# StarFive VisionFive 2 v1.3b register map
File version: 0.1
Registers are 32-bit, read-write, no defined reset value unless marked. A register's access mark holds for its fields unless they carry their own. Offsets are from the block's base; [hi:lo] are bit positions; 'fields as' and 'values as' point back to an identical list.

## starfive_jh7110_stgcrg_0 — From starfive,jh7110-stgcrg, peripheral generator
Base 0x10230000
0x00 clk_hifi4_core — Clock HIFI4 Core
  [31] clk_icg — 1: Clock enable, 0: Clock disable
0x04 clk_usb_apb — Clock USB APB
  [31] clk_icg — 1: Clock enable, 0: Clock disable
0x08 clk_usb_utmi_apb — Clock USB UTMI APB
  [31] clk_icg — 1: Clock enable, 0: Clock disable
0x0C clk_usb_axi — Clock USB AXI
  [31] clk_icg — 1: Clock enable, 0: Clock disable
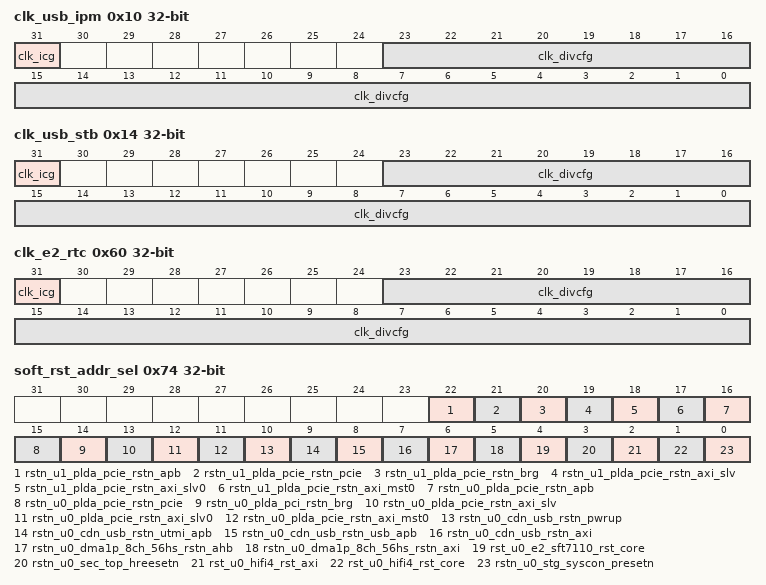
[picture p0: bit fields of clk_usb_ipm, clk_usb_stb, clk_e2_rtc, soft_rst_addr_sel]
0x10 clk_usb_ipm — Clock USB AXI
  [31] clk_icg — 1: Clock enable, 0: Clock disable
  [23:0] clk_divcfg — Clock divider coefficient: Max=2, Default=2, Min=2, Typical=2
0x14 clk_usb_stb — Clock USB STB
  [31] clk_icg — 1: Clock enable, 0: Clock disable
  [23:0] clk_divcfg — Clock divider coefficient: Max=4, Default=4, Min=4, Typical=4
0x18 clk_usb_app125 — Clock USB APP 125
  [31] clk_icg — 1: Clock enable, 0: Clock disable
0x1C clk_usb_refclk — Clock USB Reference Clock
  [23:0] clk_divcfg — Clock divider coefficient: Max=2, Default=2, Min=2, Typical=2
0x20 clk_u0_pcie_axi_mst0 — U0 Clock PCIe AXI MST 0
  [31] clk_icg — 1: Clock enable, 0: Clock disable
0x24 clk_u0_pcie_apb — U0 Clock PCIe APB
  [31] clk_icg — 1: Clock enable, 0: Clock disable
0x28 clk_u0_pcie_tl — U0 Clock PCIe TL
  [31] clk_icg — 1: Clock enable, 0: Clock disable
0x2C clk_u1_pcie_axi_mst0 — U1 Clock PCIe AXI MST 0
  [31] clk_icg — 1: Clock enable, 0: Clock disable
0x30 clk_u1_pcie_apb — U1 Clock PCIe APB
  [31] clk_icg — 1: Clock enable, 0: Clock disable
0x34 clk_u1_pcie_tl — U1 Clock PCIe TL
  [31] clk_icg — 1: Clock enable, 0: Clock disable
0x38 clk_pcie01_slv_dec_main — Clock PCIe 01 SLV DEC Main
  [31] clk_icg — 1: Clock enable, 0: Clock disable
0x3C clk_sec_hclk — Clock Security HCLK
  [31] clk_icg — 1: Clock enable, 0: Clock disable
0x40 clk_sec_misc_ahb — Clock Security Miscellaneous AHB
  [31] clk_icg — 1: Clock enable, 0: Clock disable
0x44 clk_stg_mtrx_group0_main — Clock STG MTRX Group 0 Main
  [31] clk_icg — 1: Clock enable, 0: Clock disable
0x48 clk_stg_mtrx_group0_bus — Clock STG MTRX Group 0 Bus
  [31] clk_icg — 1: Clock enable, 0: Clock disable
0x4C clk_stg_mtrx_group0_stg — Clock STG MTRX Group 0 STG
  [31] clk_icg — 1: Clock enable, 0: Clock disable
0x50 clk_stg_mtrx_group1_main — Clock STG MTRX Group 1 Main
  [31] clk_icg — 1: Clock enable, 0: Clock disable
0x54 clk_stg_mtrx_group1_bus — Clock STG MTRX Group 1 Bus
  [31] clk_icg — 1: Clock enable, 0: Clock disable
0x58 clk_stg_mtrx_group1_stg — Clock STG MTRX Group 1 STG
  [31] clk_icg — 1: Clock enable, 0: Clock disable
0x5C clk_stg_mtrx_group1_hifi — Clock STG MTRX Group 1 HIFI
  [31] clk_icg — 1: Clock enable, 0: Clock disable
0x60 clk_e2_rtc — Clock E2 RTC
  [31] clk_icg — 1: Clock enable, 0: Clock disable
  [23:0] clk_divcfg — Clock divider coefficient: Max=24, Default=24, Min=24, Typical=24
0x64 clk_e2_core — Clock E2 Core
  [31] clk_icg — 1: Clock enable, 0: Clock disable
0x68 clk_e2_dbg — Clock E2 DBG
  [31] clk_icg — 1: Clock enable, 0: Clock disable
0x6C clk_dma_axi — Clock DMA AXI
  [31] clk_icg — 1: Clock enable, 0: Clock disable
0x70 clk_dma_ahb — Clock DMA AHB
  [31] clk_icg — 1: Clock enable, 0: Clock disable
0x74 soft_rst_addr_sel — Software RESET Address Selector
  [22] rstn_u1_plda_pcie_rstn_apb — 1: Assert reset, 0: De-assert reset
  [21] rstn_u1_plda_pcie_rstn_pcie — 1: Assert reset, 0: De-assert reset
  [20] rstn_u1_plda_pcie_rstn_brg — 1: Assert reset, 0: De-assert reset
  [19] rstn_u1_plda_pcie_rstn_axi_slv — 1: Assert reset, 0: De-assert reset
  [18] rstn_u1_plda_pcie_rstn_axi_slv0 — 1: Assert reset, 0: De-assert reset
  [17] rstn_u1_plda_pcie_rstn_axi_mst0 — 1: Assert reset, 0: De-assert reset
  [16] rstn_u0_plda_pcie_rstn_apb — 1: Assert reset, 0: De-assert reset
  [15] rstn_u0_plda_pcie_rstn_pcie — 1: Assert reset, 0: De-assert reset
  [14] rstn_u0_plda_pci_rstn_brg — 1: Assert reset, 0: De-assert reset
  [13] rstn_u0_plda_pcie_rstn_axi_slv — 1: Assert reset, 0: De-assert reset
  [12] rstn_u0_plda_pcie_rstn_axi_slv0 — 1: Assert reset, 0: De-assert reset
  [11] rstn_u0_plda_pcie_rstn_axi_mst0 — 1: Assert reset, 0: De-assert reset
  [10] rstn_u0_cdn_usb_rstn_pwrup — 1: Assert reset, 0: De-assert reset
  [9] rstn_u0_cdn_usb_rstn_utmi_apb — 1: Assert reset, 0: De-assert reset
  [8] rstn_u0_cdn_usb_rstn_usb_apb — 1: Assert reset, 0: De-assert reset
  [7] rstn_u0_cdn_usb_rstn_axi — 1: Assert reset, 0: De-assert reset
  [6] rstn_u0_dma1p_8ch_56hs_rstn_ahb — 1: Assert reset, 0: De-assert reset
  [5] rstn_u0_dma1p_8ch_56hs_rstn_axi — 1: Assert reset, 0: De-assert reset
  [4] rst_u0_e2_sft7110_rst_core — 1: Assert reset, 0: De-assert reset
  [3] rstn_u0_sec_top_hreesetn — 1: Assert reset, 0: De-assert reset
  [2] rst_u0_hifi4_rst_axi — 1: Assert reset, 0: De-assert reset
  [1] rst_u0_hifi4_rst_core — 1: Assert reset, 0: De-assert reset
  [0] rstn_u0_stg_syscon_presetn — 1: Assert reset, 0: De-assert reset
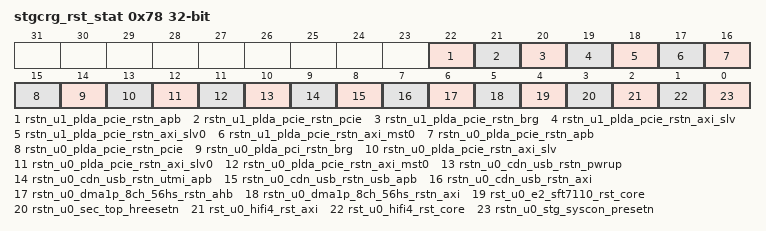
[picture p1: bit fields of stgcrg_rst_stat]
0x78 stgcrg_rst_stat — STGCRG RESET Status
  fields as soft_rst_addr_sel
